AUTOSAR XML (schema 00050)
package /IBNvBlkSWC_3
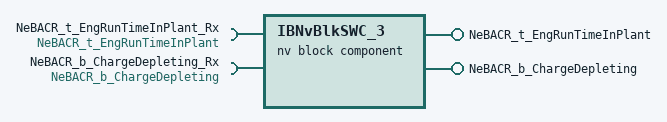
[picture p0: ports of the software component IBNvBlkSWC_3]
  nv block sw component type IBNvBlkSWC_3
    provide port NeBACR_t_EngRunTimeInPlant: nv-provide-com-spec{ram-block-init-value=Value:4294967295, rom-block-init-value=Value:4294967295, variable=NeBACR_t_EngRunTimeInPlant}, provided-interface=NeBACR_t_EngRunTimeInPlant
    require port NeBACR_t_EngRunTimeInPlant_Rx: nv-require-com-spec{init-value=Value:4294967295, variable=NeBACR_t_EngRunTimeInPlant}, required-interface=NeBACR_t_EngRunTimeInPlant
    provide port NeBACR_b_ChargeDepleting: nv-provide-com-spec{ram-block-init-value=Value:1, rom-block-init-value=Value:1, variable=NeBACR_b_ChargeDepleting}, provided-interface=NeBACR_b_ChargeDepleting
    require port NeBACR_b_ChargeDepleting_Rx: nv-require-com-spec{init-value=Value:1, variable=NeBACR_b_ChargeDepleting}, required-interface=NeBACR_b_ChargeDepleting
    behavior IB_NvBlkSWC_3: data-type-mapping=NVM_DataMappingSet, handle-termination-and-restart=NO-SUPPORT
    nv block descriptor ExpendableNonVolatile_Descr_Core3: support-dirty-flag=true
      nv-block-data-mappings:
        {nv-ram-block-element=autosar-variable-in-impl-datatype={root-variable-data-prototype=ExpendableNonVolatile_RamBlock_Core3, target-data-prototype=ExpendableNonVolatile_Ram_Core3/NeBACR_t_EngRunTimeInPlant}, read-nv-data=NeBACR_t_EngRunTimeInPlant.NeBACR_t_EngRunTimeInPlant}
        {nv-ram-block-element=autosar-variable-in-impl-datatype={root-variable-data-prototype=ExpendableNonVolatile_RamBlock_Core3, target-data-prototype=ExpendableNonVolatile_Ram_Core3/NeBACR_t_EngRunTimeInPlant}, written-nv-data=NeBACR_t_EngRunTimeInPlant_Rx.NeBACR_t_EngRunTimeInPlant}
        {nv-ram-block-element=autosar-variable-in-impl-datatype={root-variable-data-prototype=ExpendableNonVolatile_RamBlock_Core3, target-data-prototype=ExpendableNonVolatile_Ram_Core3/NeBACR_b_ChargeDepleting}, read-nv-data=NeBACR_b_ChargeDepleting.NeBACR_b_ChargeDepleting}
        {nv-ram-block-element=autosar-variable-in-impl-datatype={root-variable-data-prototype=ExpendableNonVolatile_RamBlock_Core3, target-data-prototype=ExpendableNonVolatile_Ram_Core3/NeBACR_b_ChargeDepleting}, written-nv-data=NeBACR_b_ChargeDepleting_Rx.NeBACR_b_ChargeDepleting}
      nv block needs NvBlockNeeds: calc-ram-block-crc=false, check-static-block-id=false, readonly=false, resistant-to-changed-sw=false, restore-at-start=true, store-at-shutdown=true, store-cyclic=false, store-emergency=false, store-immediate=false, use-auto-validation-at-shut-down=false, use-crc-comp-mechanism=true, write-only-once=false, write-verification=false
      ram block ExpendableNonVolatile_RamBlock_Core3: type=ExpendableNonVolatile_Ram_Core3, init-value={short-label=ExpendableNonVolatile_Ram_Core3, fields=[NeBACR_t_EngRunTimeInPlant:4294967295, NeBACR_b_ChargeDepleting:1, Reserved1:0, Reserved2:0, Reserved3:0, Reserved4:0, Reserved5:0, Reserved6:0, Reserved7:0, Reserved8:0, Reserved9:0, Reserved10:0, Reserved11:0, Reserved12:0, Reserved13:0, Reserved14:0, Reserved15:0, Reserved16:0, Reserved17:0, Reserved18:0, Reserved19:0, Reserved20:0, Reserved21:0, Reserved22:0, Reserved23:0, Reserved24:0, Reserved25:0, Reserved26:0, Reserved27:0]}
      rom block ExpendableNonVolatile_RomBlock_Core3: type=ExpendableNonVolatile_Rom_Core3, init-value={short-label=ExpendableNonVolatile_Rom_Core3, fields=[NeBACR_t_EngRunTimeInPlant:4294967295, NeBACR_b_ChargeDepleting:1, Reserved1:0, Reserved2:0, Reserved3:0, Reserved4:0, Reserved5:0, Reserved6:0, Reserved7:0, Reserved8:0, Reserved9:0, Reserved10:0, Reserved11:0, Reserved12:0, Reserved13:0, Reserved14:0, Reserved15:0, Reserved16:0, Reserved17:0, Reserved18:0, Reserved19:0, Reserved20:0, Reserved21:0, Reserved22:0, Reserved23:0, Reserved24:0, Reserved25:0, Reserved26:0, Reserved27:0]}
package /IFEepNVBlk_3
  impl type ExpendableNonVolatile_Ram_Core3: category=STRUCTURE
    29 x element, all with category=TYPE_REFERENCE:
      NeBACR_t_EngRunTimeInPlant: implementation-data-type=float32
      NeBACR_b_ChargeDepleting: implementation-data-type=boolean
      Reserved{1..27}: implementation-data-type=uint8
  impl type ExpendableNonVolatile_Rom_Core3: category=STRUCTURE
    29 x element, all with category=TYPE_REFERENCE:
      NeBACR_t_EngRunTimeInPlant: implementation-data-type=float32
      NeBACR_b_ChargeDepleting: implementation-data-type=boolean
      Reserved{1..27}: implementation-data-type=uint8
